VERSION ""

NS_ :

BS_:

BU_:

BO_ 3221225472 VECTOR__INDEPENDENT_SIG_MSG: 0 Vector__XXX
 SG_ New_Signal_64 : 0|24@0+ (1,0) [0|16777215] "" Vector__XXX
 SG_ Thermistor_2 : 0|16@1+ (0.1,0) [0|6553.5] "Deg Cel" Vector__XXX
 SG_ Thermistor_1 : 0|16@1+ (0.1,0) [0|6553.5] "Deg Cel" Vector__XXX

BO_ 285 Balancing_Bit_Mask: 3 Vector__XXX
 SG_ Balancing_Mask_Indication : 0|24@1+ (1,0) [0|16777215] "" Vector__XXX

BO_ 284 Battery_Capacity_Info: 8 Vector__XXX
 SG_ Full_Pack_Capacity : 16|16@1+ (0.1,0) [0|6553.5] "Ah" Vector__XXX

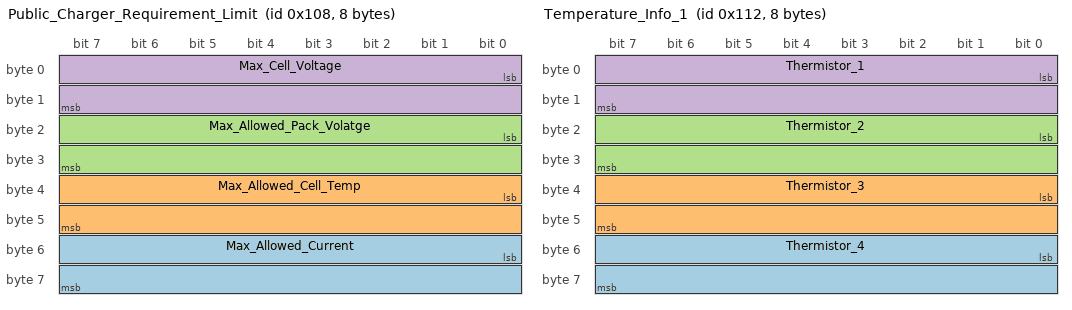
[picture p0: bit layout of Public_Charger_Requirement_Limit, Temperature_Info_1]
BO_ 264 Public_Charger_Requirement_Limit: 8 Vector__XXX
 SG_ Max_Allowed_Current : 48|16@1+ (1,0) [0|65535] "A" Vector__XXX
 SG_ Max_Allowed_Cell_Temp : 32|16@1+ (1,0) [0|65535] "Deg Cel" Vector__XXX
 SG_ Max_Allowed_Pack_Volatge : 16|16@1+ (1,0) [0|65535] "V" Vector__XXX
 SG_ Max_Cell_Voltage : 0|16@1+ (1,0) [0|65535] "mV" Vector__XXX

BO_ 2566848976 Voltage_Info: 8 Vector__XXX
 SG_ Min_Cell_Voltage : 39|16@0+ (1,0) [0|65535] "mV" Vector__XXX

BO_ 290 Temperature_Info_2: 4 Vector__XXX
 SG_ Available_Discharge_Energy : 16|16@1+ (1,0) [0|65535] "Wh" Vector__XXX
 SG_ Thermistor_5 : 0|16@1+ (0.1,0) [-128.0|127.0] "degC" Vector__XXX

BO_ 274 Temperature_Info_1: 8 Vector__XXX
 SG_ Thermistor_4 : 48|16@1+ (0.1,0) [-128.0|127.0] "degC" Vector__XXX
 SG_ Thermistor_3 : 32|16@1+ (0.1,0) [-128.0|127.0] "degC" Vector__XXX
 SG_ Thermistor_2 : 16|16@1+ (0.1,0) [-128.0|127.0] "degC" Vector__XXX
 SG_ Thermistor_1 : 0|16@1+ (0.1,0) [-128.0|127.0] "degC" Vector__XXX

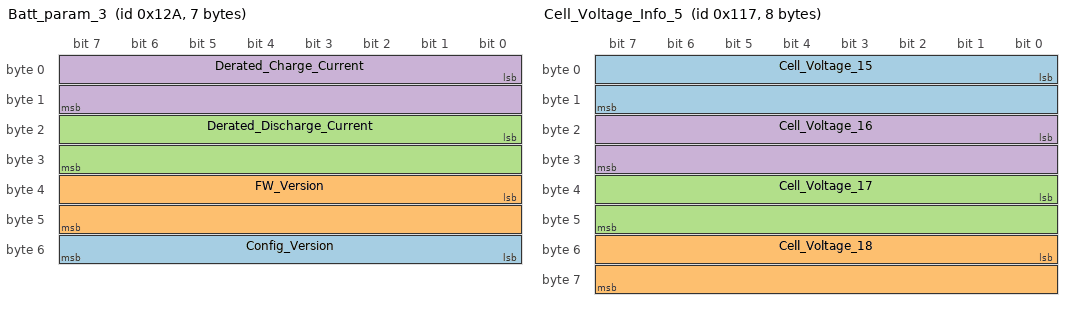
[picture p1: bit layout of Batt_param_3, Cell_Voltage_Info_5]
BO_ 298 Batt_param_3: 7 Vector__XXX
 SG_ Config_Version : 48|8@1+ (1,0) [0|255] "" Vector__XXX
 SG_ FW_Version : 32|16@1+ (1,0) [0|65535] "" Vector__XXX
 SG_ Derated_Discharge_Current : 16|16@1+ (0.1,0) [0|655.35] "A" Vector__XXX
 SG_ Derated_Charge_Current : 0|16@1+ (0.1,0) [0|655.35] "A" Vector__XXX

BO_ 280 Cell_Voltage_Info_6: 4 Vector__XXX
 SG_ Cell_Voltage_20 : 16|16@1+ (0.1,0) [0|6553.5] "mV" Vector__XXX
 SG_ Cell_Voltage_19 : 0|16@1+ (0.1,0) [0|6553.5] "mV" Vector__XXX

BO_ 279 Cell_Voltage_Info_5: 8 Vector__XXX
 SG_ Cell_Voltage_15 : 0|16@1+ (0.1,0) [0|6553.5] "mV" Vector__XXX
 SG_ Cell_Voltage_18 : 48|16@1+ (0.1,0) [0|6553.5] "mV" Vector__XXX
 SG_ Cell_Voltage_17 : 32|16@1+ (0.1,0) [0|6553.5] "mV" Vector__XXX
 SG_ Cell_Voltage_16 : 16|16@1+ (0.1,0) [0|6553.5] "mV" Vector__XXX

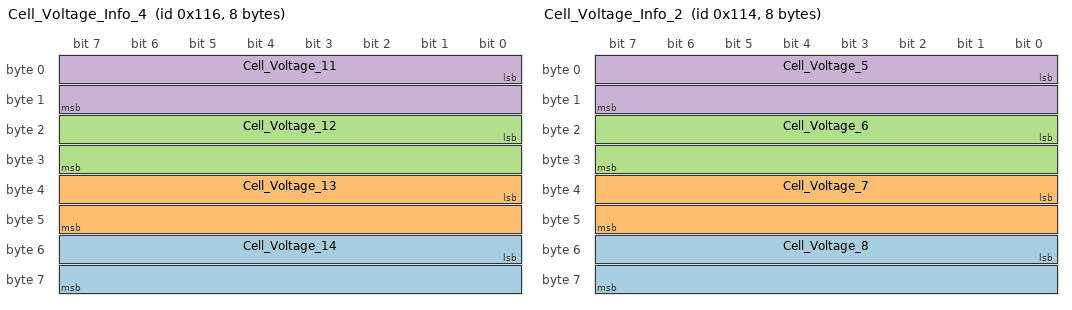
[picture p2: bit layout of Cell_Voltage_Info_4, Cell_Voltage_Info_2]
BO_ 278 Cell_Voltage_Info_4: 8 Vector__XXX
 SG_ Cell_Voltage_14 : 48|16@1+ (0.1,0) [0|6553.5] "mV" Vector__XXX
 SG_ Cell_Voltage_13 : 32|16@1+ (0.1,0) [0|6553.5] "mV" Vector__XXX
 SG_ Cell_Voltage_12 : 16|16@1+ (0.1,0) [0|6553.5] "mV" Vector__XXX
 SG_ Cell_Voltage_11 : 0|16@1+ (0.1,0) [0|6553.5] "mV" Vector__XXX

BO_ 277 Cell_Voltage_Info_3: 4 Vector__XXX
 SG_ Cell_Voltage_9 : 0|16@1+ (0.1,0) [0|6553.5] "mV" Vector__XXX
 SG_ Cell_Voltage_10 : 16|16@1+ (0.1,0) [0|6553.5] "mV" Vector__XXX

BO_ 276 Cell_Voltage_Info_2: 8 Vector__XXX
 SG_ Cell_Voltage_8 : 48|16@1+ (0.1,0) [0|6553.5] "mV" Vector__XXX
 SG_ Cell_Voltage_7 : 32|16@1+ (0.1,0) [0|6553.5] "mV" Vector__XXX
 SG_ Cell_Voltage_6 : 16|16@1+ (0.1,0) [0|6553.5] "mV" Vector__XXX
 SG_ Cell_Voltage_5 : 0|16@1+ (0.1,0) [0|6553.5] "mV" Vector__XXX

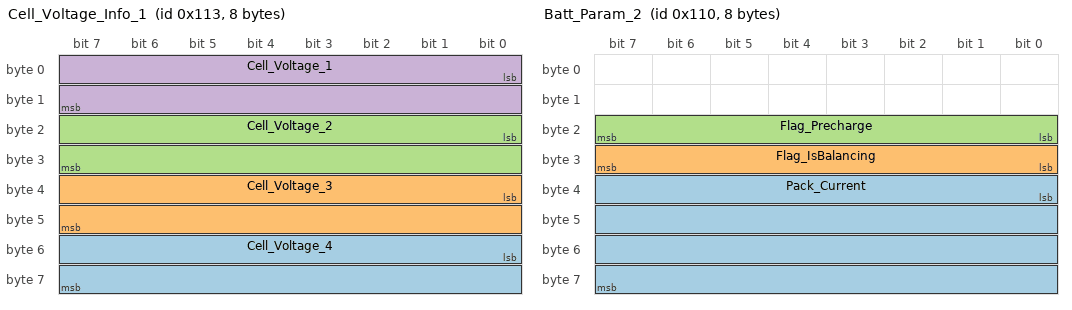
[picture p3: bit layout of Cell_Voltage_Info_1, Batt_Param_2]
BO_ 275 Cell_Voltage_Info_1: 8 Vector__XXX
 SG_ Cell_Voltage_4 : 48|16@1+ (0.1,0) [0|6553.5] "mV" Vector__XXX
 SG_ Cell_Voltage_3 : 32|16@1+ (0.1,0) [0|6553.5] "mV" Vector__XXX
 SG_ Cell_Voltage_2 : 16|16@1+ (0.1,0) [0|6553.5] "mV" Vector__XXX
 SG_ Cell_Voltage_1 : 0|16@1+ (0.1,0) [0|6553.5] "mV" Vector__XXX

BO_ 272 Batt_Param_2: 8 Vector__XXX
 SG_ Pack_Current : 32|32@1- (1e-005,0) [-21474.8|21474.8] "A" Vector__XXX
 SG_ Flag_IsBalancing : 24|8@1+ (1,0) [0|1] "" Vector__XXX
 SG_ Flag_Precharge : 16|8@1+ (1,0) [0|1] "" Vector__XXX

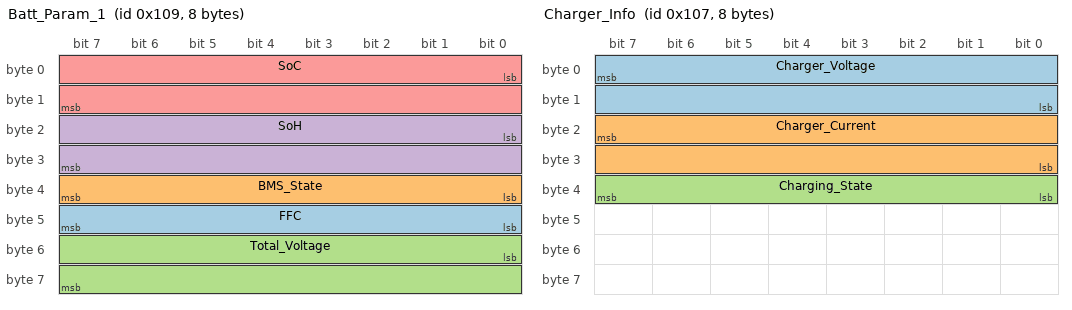
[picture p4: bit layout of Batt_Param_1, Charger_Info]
BO_ 265 Batt_Param_1: 8 Vector__XXX
 SG_ FFC : 40|8@1+ (1,0) [0|0] "" Vector__XXX
 SG_ BMS_State : 32|8@1+ (1,0) [0|0] "" Vector__XXX
 SG_ Total_Voltage : 48|16@1+ (0.1,0) [0|6553.5] "V" Vector__XXX
 SG_ SoH : 16|16@1+ (0.01,0) [0|655.35] "%" Vector__XXX
 SG_ SoC : 0|16@1+ (0.01,0) [0|655.35] "%" Vector__XXX

VAL_ 265 Flag_Fully_Charged  0 "False" 1 "True" ;
VAL_ 265 BMS_State           0 "INIT" 1 "Ready" 2 "Precharge" 3 "Active" 4 "Error" ;

BO_ 263 Charger_Info: 8 Vector__XXX
 SG_ Charger_Voltage : 7|16@0+ (0.1,0) [0|6553.5] "V" Vector__XXX
 SG_ Charger_Current : 23|16@0+ (0.1,0) [0|6553.5] "A" Vector__XXX
 SG_ Charging_State : 39|8@0+ (1,0) [0|255] "" Vector__XXX

BO_ 614 ERR_DateValidation: 1 Vector__XXX
 SG_ DateValidation : 0|8@1+ (1,0) [0|1] "" Vector__XXX

BO_ 613 ERR_PDUOverTemperature: 1 Vector__XXX
 SG_ PDUOverTemperature : 0|8@1+ (1,0) [0|1] "" Vector__XXX

BO_ 612 ERR_PDUFailure: 1 Vector__XXX
 SG_ PDUFailure : 0|8@1+ (1,0) [0|1] "" Vector__XXX

BO_ 611 ERR_OpenConnection: 1 Vector__XXX
 SG_ OpenConnection : 0|8@1+ (1,0) [0|1] "" Vector__XXX

BO_ 610 ERR_JsonParseError: 1 Vector__XXX
 SG_ JsonParseError : 0|8@1+ (1,0) [0|1] "" Vector__XXX

BO_ 609 ERR_CurrentOutdated: 1 Vector__XXX
 SG_ CurrentOutdated : 0|8@1+ (1,0) [0|1] "" Vector__XXX

BO_ 608 ERR_BoardValuesOutdated: 1 Vector__XXX
 SG_ BoardValuesOutdated : 0|8@1+ (1,0) [0|1] "" Vector__XXX

BO_ 607 ERR_BMSDataOutdated: 1 Vector__XXX
 SG_ BMSDataOutdated : 0|8@1+ (1,0) [0|1] "" Vector__XXX

BO_ 606 ERR_ShortCircuit: 1 Vector__XXX
 SG_ ShortCircuit : 0|8@1+ (1,0) [0|1] "" Vector__XXX

BO_ 605 ERR_Overload: 1 Vector__XXX
 SG_ Overload : 0|8@1+ (1,0) [0|1] "" Vector__XXX

BO_ 604 ERR_OverTemperature: 1 Vector__XXX
 SG_ OverTemperature : 0|8@1+ (1,0) [0|1] "" Vector__XXX

BO_ 603 ERR_UnderVoltage: 1 Vector__XXX
 SG_ UnderVoltage : 0|8@1+ (1,0) [0|1] "" Vector__XXX

BO_ 602 ERR_OverVoltage: 1 Vector__XXX
 SG_ OverVoltage : 0|8@1+ (1,0) [0|1] "" Vector__XXX

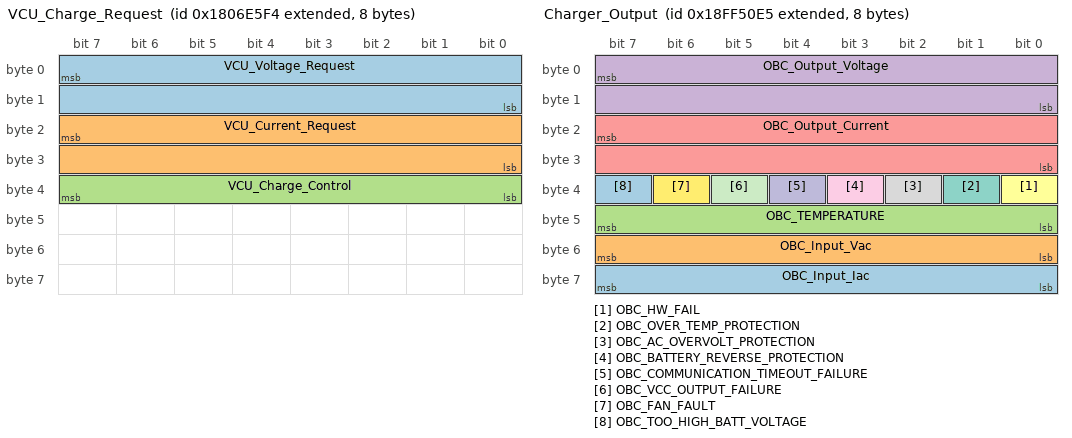
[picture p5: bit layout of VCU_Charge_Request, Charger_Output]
BO_ 2550588916 VCU_Charge_Request: 8 Vector__XXX
 SG_ VCU_Voltage_Request : 7|16@0+ (0.1,0) [0|6553.5] "V" Vector__XXX
 SG_ VCU_Current_Request : 23|16@0+ (0.1,0) [0|6553.5] "A" Vector__XXX
 SG_ VCU_Charge_Control  : 39|8@0+ (1,0) [0|1] "" Vector__XXX

BO_ 2566869221 Charger_Output: 8 Vector__XXX
 SG_ OBC_Input_Iac : 63|8@0+ (0.1,0) [0|25.5] "A" Vector__XXX
 SG_ OBC_Input_Vac : 55|8@0+ (2,0) [0|510] "V" Vector__XXX
 SG_ OBC_TEMPERATURE : 47|8@0+ (1,-100) [-100|155] "°C" Vector__XXX
 SG_ OBC_Output_Voltage : 7|16@0+ (0.1,0) [0|6553.5] "V" Vector__XXX
 SG_ OBC_Output_Current : 23|16@0+ (0.1,0) [0|6553.5] "A" Vector__XXX
 SG_ OBC_HW_FAIL : 32|1@0- (1,0) [0|1] "" Vector__XXX
 SG_ OBC_OVER_TEMP_PROTECTION : 33|1@0- (1,0) [0|1] "" Vector__XXX
 SG_ OBC_AC_OVERVOLT_PROTECTION : 34|1@0- (1,0) [0|1] "" Vector__XXX
 SG_ OBC_BATTERY_REVERSE_PROTECTION : 35|1@0- (1,0) [0|1] "" Vector__XXX
 SG_ OBC_COMMUNICATION_TIMEOUT_FAILURE : 36|1@0- (1,0) [0|1] "" Vector__XXX
 SG_ OBC_VCC_OUTPUT_FAILURE : 37|1@0- (1,0) [0|1] "" Vector__XXX
 SG_ OBC_FAN_FAULT : 38|1@0- (1,0) [0|1] "" Vector__XXX
 SG_ OBC_TOO_HIGH_BATT_VOLTAGE : 39|1@0- (1,0) [0|1] "" Vector__XXX

BO_ 1571 GPIO_DCDC_OUT : 8 Vector__XXX
 SG_ DCDC_OUT :10|1@1+ (1,0) [0|0] "" Vector__XXX

BO_ 2554393600 VCU_Ignition_Command: 8 Vector__XXX
 SG_ VCU_Ignition_Status : 40|1@1+ (1,0) [0|1] "" Vector__XXX
 SG_ VCU_Shutdown_Counter : 56|8@1+ (1,0) [0|255] "" Vector__XXX
VAL_ 2554393600 VCU_Ignition_Status 0 "Ignition OFF Command" 1 "Ignition ON Command";

BO_ 1542 AuxVoltage: 8 Vector__XXX
 SG_ Aux_Voltage : 15|16@0+ (0.01,0) [0|655.35] "V" Vector__XXX

BO_ 1813 MCU_CAP_RPM: 8 Vector__XXX
 SG_ MCU_BATT_KSI : 40|8@1+ (1,0) [0|255] "V" Vector__XXX
 SG_ MCU_CAP_Volt : 32|8@1+ (1,0) [0|255] "V" Vector__XXX

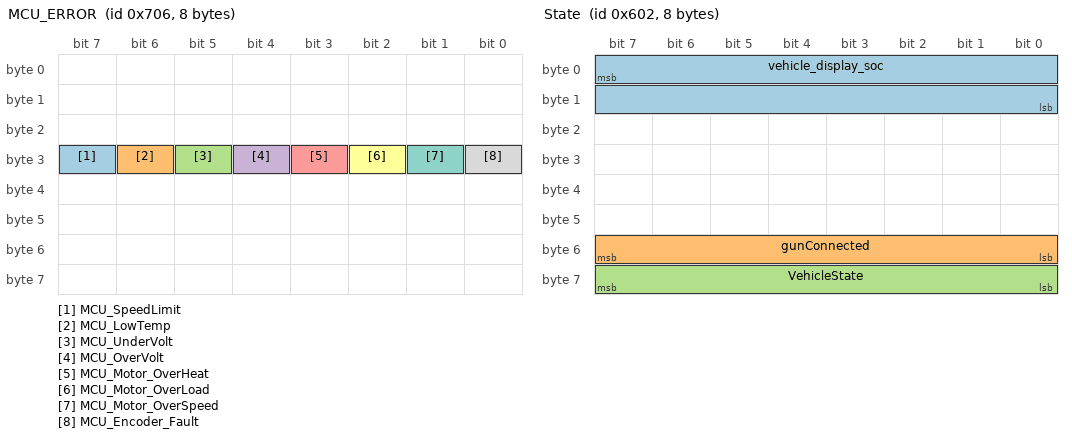
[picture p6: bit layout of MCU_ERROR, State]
BO_ 1798 MCU_ERROR: 8 Vector__XXX
 SG_ MCU_SpeedLimit : 31|1@1+ (1,0) [0|1] "" Vector__XXX
 SG_ MCU_LowTemp : 30|1@1+ (1,0) [0|1] "" Vector__XXX
 SG_ MCU_UnderVolt : 29|1@1+ (1,0) [0|1] "" Vector__XXX
 SG_ MCU_OverVolt : 28|1@1+ (1,0) [0|1] "" Vector__XXX
 SG_ MCU_Motor_OverHeat : 27|1@1+ (1,0) [0|1] "" Vector__XXX
 SG_ MCU_Motor_OverLoad : 26|1@1+ (1,0) [0|1] "" Vector__XXX
 SG_ MCU_Motor_OverSpeed : 25|1@1+ (1,0) [0|1] "" Vector__XXX
 SG_ MCU_Encoder_Fault : 24|1@1+ (1,0) [0|1] "" Vector__XXX

BO_ 1538 State: 8 Vector__XXX
 SG_ vehicle_display_soc : 7|16@0+ (0.1,0) [0|0] "" Vector__XXX
 SG_ gunConnected : 48|8@1- (1,0) [0|0] "" Vector__XXX
 SG_ VehicleState : 56|8@1+ (1,0) [0|0] "" Vector__XXX
VAL_ 1538 VehicleState           0 "Off" 1 "Charge" 2 "Drive" 3 "Full Charge" 4 "Deep_Sleep" ;

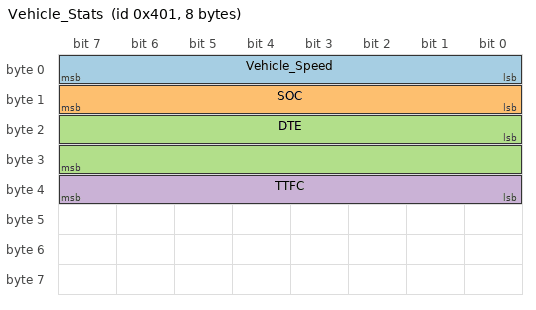
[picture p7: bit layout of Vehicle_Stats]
BO_ 1025 Vehicle_Stats: 8 Vector__XXX
 SG_ Vehicle_Speed : 0|8@1+ (1,0) [0|255] "km/h" Vector__XXX
 SG_ SOC           : 8|8@1+ (1,0) [0|100] "%"    Vector__XXX
 SG_ DTE           : 16|16@1+ (0.1,0) [0|6553.5] "min" Vector__XXX
 SG_ TTFC          : 32|8@1+ (1,0) [0|255] "min" Vector__XXX
